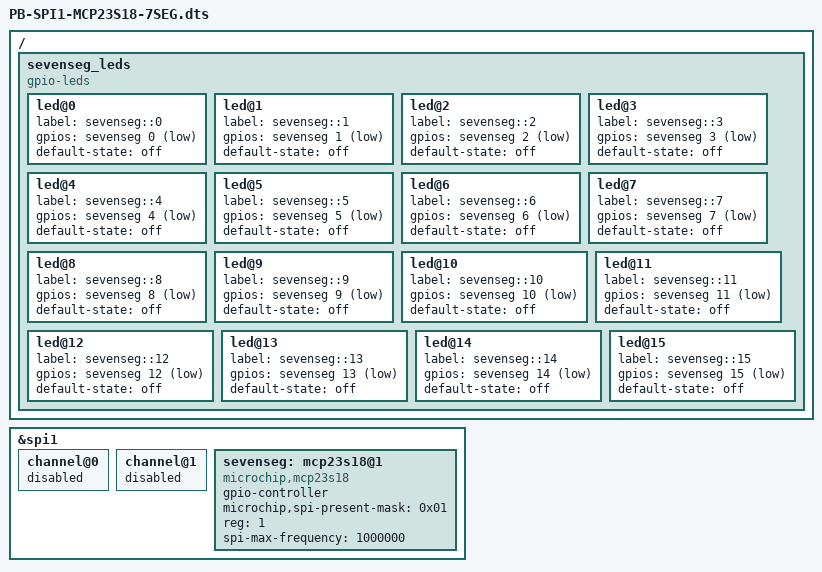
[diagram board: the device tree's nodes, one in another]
/*
 * Copyright (C) 2017 Robert Nelson <robertcnelson@gmail.com>
 * Copyright (C) 2019 Texas Instruments, Jason Kridner <jdk@ti.com>
 *
 * This program is free software; you can redistribute it and/or modify
 * it under the terms of the GNU General Public License version 2 as
 * published by the Free Software Foundation.
 *
 * For PocketBeagle BaconBits and TechLab capes. Based on
 * PB-SPI1-RTC-5-CLICK.dts and
 * https://github.com/e-ale/Code/blob/master/RESOURCES/spi-drivers/spi-gpio.dts
 */

/dts-v1/;
/plugin/;

#include <dt-bindings/gpio/gpio.h>
#include <dt-bindings/pinctrl/am33xx.h>
#include <dt-bindings/interrupt-controller/irq.h>

/ {
#if 0
	/*
	 * Free up the pins used by the cape from the pinmux helpers.
	 */
	fragment@0 {
		target = <&ocp>;
		__overlay__ {
			P2_25_pinmux { status = "disabled"; };
			P2_27_pinmux { status = "disabled"; };
			P2_29_pinmux { status = "disabled"; };
			P2_31_pinmux { status = "disabled"; };
		};
	};

	fragment@2 {
		target = <&am33xx_pinmux>;
		__overlay__ {
			pb_spi1_pins: pinmux_pb_spi1_pins {
				pinctrl-single,pins = <
					AM33XX_IOPAD(0x0964, PIN_INPUT | MUX_MODE4 ) /* (C18) eCAP0_in_PWM0_out.spi1_sclk */
					AM33XX_IOPAD(0x0968, PIN_INPUT | MUX_MODE4 ) /* (E18) uart0_ctsn.spi1_d0 */
					AM33XX_IOPAD(0x096c, PIN_INPUT | MUX_MODE4 ) /* (E17) uart0_rtsn.spi1_d1 */
					AM33XX_IOPAD(0x09b0, PIN_INPUT | MUX_MODE4 ) /* (A15) xdma_event_intr0.spi1_cs1 */
				>;
			};
		};
	};
#endif

	fragment@3 {
		target = <&spi1>;
		__overlay__ {
			status = "okay";
#if 0
			pinctrl-names = "default";
			pinctrl-0 = <&pb_spi1_pins>;
#endif

			channel@0{ status = "disabled"; };
			channel@1{ status = "disabled"; };
		};
	};

	fragment@4 {
		target = <&spi1>;
		__overlay__ {
			#address-cells = <1>;
			#size-cells = <0>;

			sevenseg: mcp23s18@1 {
				#address-cells = <1>;
				#size-cells = <1>;
				#gpio-cells = <2>;
				compatible = "microchip,mcp23s18";
				gpio-controller;
				microchip,spi-present-mask = <0x01>;
				reg = <1>;
				spi-max-frequency = <1000000>;
			};
		};
	};

	/*
	 * Load the drivers for the LEDs.
	 */
	fragment@5 {
		target-path="/";
		__overlay__ {
			sevenseg_leds {
				compatible = "gpio-leds";

				led@0 {
					label = "sevenseg::0";
					gpios = <&sevenseg 0 GPIO_ACTIVE_LOW>;
					default-state = "off";
				};

				led@1 {
					label = "sevenseg::1";
					gpios = <&sevenseg 1 GPIO_ACTIVE_LOW>;
					default-state = "off";
				};

				led@2 {
					label = "sevenseg::2";
					gpios = <&sevenseg 2 GPIO_ACTIVE_LOW>;
					default-state = "off";
				};

				led@3 {
					label = "sevenseg::3";
					gpios = <&sevenseg 3 GPIO_ACTIVE_LOW>;
					default-state = "off";
				};

				led@4 {
					label = "sevenseg::4";
					gpios = <&sevenseg 4 GPIO_ACTIVE_LOW>;
					default-state = "off";
				};

				led@5 {
					label = "sevenseg::5";
					gpios = <&sevenseg 5 GPIO_ACTIVE_LOW>;
					default-state = "off";
				};

				led@6 {
					label = "sevenseg::6";
					gpios = <&sevenseg 6 GPIO_ACTIVE_LOW>;
					default-state = "off";
				};

				led@7 {
					label = "sevenseg::7";
					gpios = <&sevenseg 7 GPIO_ACTIVE_LOW>;
					default-state = "off";
				};

				led@8 {
					label = "sevenseg::8";
					gpios = <&sevenseg 8 GPIO_ACTIVE_LOW>;
					default-state = "off";
				};

				led@9 {
					label = "sevenseg::9";
					gpios = <&sevenseg 9 GPIO_ACTIVE_LOW>;
					default-state = "off";
				};

				led@10 {
					label = "sevenseg::10";
					gpios = <&sevenseg 10 GPIO_ACTIVE_LOW>;
					default-state = "off";
				};

				led@11 {
					label = "sevenseg::11";
					gpios = <&sevenseg 11 GPIO_ACTIVE_LOW>;
					default-state = "off";
				};

				led@12 {
					label = "sevenseg::12";
					gpios = <&sevenseg 12 GPIO_ACTIVE_LOW>;
					default-state = "off";
				};

				led@13 {
					label = "sevenseg::13";
					gpios = <&sevenseg 13 GPIO_ACTIVE_LOW>;
					default-state = "off";
				};

				led@14 {
					label = "sevenseg::14";
					gpios = <&sevenseg 14 GPIO_ACTIVE_LOW>;
					default-state = "off";
				};

				led@15 {
					label = "sevenseg::15";
					gpios = <&sevenseg 15 GPIO_ACTIVE_LOW>;
					default-state = "off";
				};
			};
		};
	};
};
